# Espressif register map
File version: 1.0
CPU: Xtensa LX6 1, little endian, no MPU, FPU, 3 interrupt priority bits
Registers are 32-bit, access not given, reset 0x0 unless marked. A register's access mark holds for its fields unless they carry their own. Offsets are from the block's base; [hi:lo] are bit positions; {n}, {i} and the like mark numbered series.

## RTCCNTL
Base 0x3FF48000
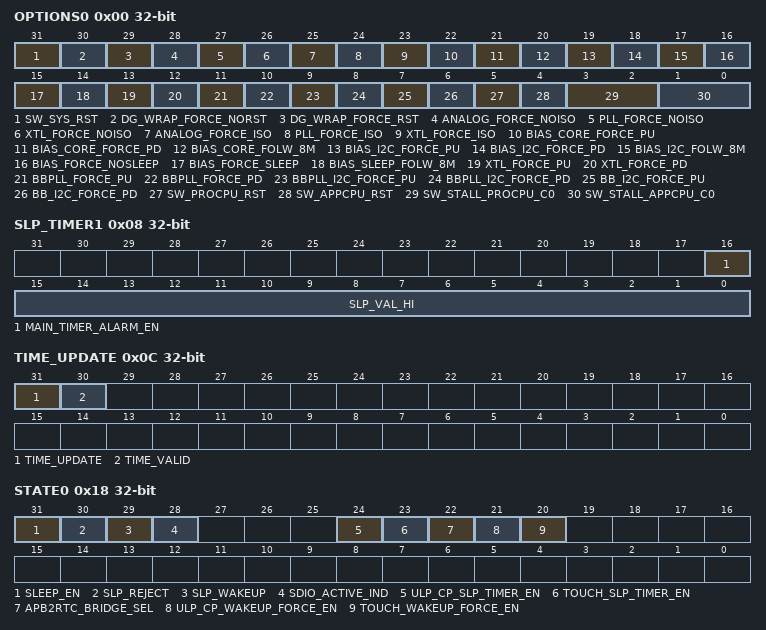
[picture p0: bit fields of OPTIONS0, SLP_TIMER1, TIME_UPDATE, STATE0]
0x00 OPTIONS0 — RTC_CNTL_OPTIONS0
  [31] SW_SYS_RST, [30] DG_WRAP_FORCE_NORST, [29] DG_WRAP_FORCE_RST, [28] ANALOG_FORCE_NOISO, [27] PLL_FORCE_NOISO, [26] XTL_FORCE_NOISO, [25] ANALOG_FORCE_ISO, [24] PLL_FORCE_ISO, [23] XTL_FORCE_ISO, [22] BIAS_CORE_FORCE_PU, [21] BIAS_CORE_FORCE_PD, [20] BIAS_CORE_FOLW_8M, [19] BIAS_I2C_FORCE_PU, [18] BIAS_I2C_FORCE_PD, [17] BIAS_I2C_FOLW_8M, [16] BIAS_FORCE_NOSLEEP, [15] BIAS_FORCE_SLEEP, [14] BIAS_SLEEP_FOLW_8M, [13] XTL_FORCE_PU, [12] XTL_FORCE_PD, [11] BBPLL_FORCE_PU, [10] BBPLL_FORCE_PD, [9] BBPLL_I2C_FORCE_PU, [8] BBPLL_I2C_FORCE_PD, [7] BB_I2C_FORCE_PU, [6] BB_I2C_FORCE_PD, [5] SW_PROCPU_RST, [4] SW_APPCPU_RST, [3:2] SW_STALL_PROCPU_C0, [1:0] SW_STALL_APPCPU_C0
0x04 SLP_TIMER0 — RTC_CNTL_SLP_TIMER0
  [31:0] SLP_VAL_LO
0x08 SLP_TIMER1 — RTC_CNTL_SLP_TIMER1
  [16] MAIN_TIMER_ALARM_EN, [15:0] SLP_VAL_HI
0x0C TIME_UPDATE — RTC_CNTL_TIME_UPDATE
  [31] TIME_UPDATE, [30] TIME_VALID
0x10 TIME0 — RTC_CNTL_TIME0
  [31:0] TIME_LO
0x14 TIME1 — RTC_CNTL_TIME1
  [15:0] TIME_HI
0x18 STATE0 — RTC_CNTL_STATE0
  [31] SLEEP_EN, [30] SLP_REJECT, [29] SLP_WAKEUP, [28] SDIO_ACTIVE_IND, [24] ULP_CP_SLP_TIMER_EN, [23] TOUCH_SLP_TIMER_EN, [22] APB2RTC_BRIDGE_SEL, [21] ULP_CP_WAKEUP_FORCE_EN, [20] TOUCH_WAKEUP_FORCE_EN
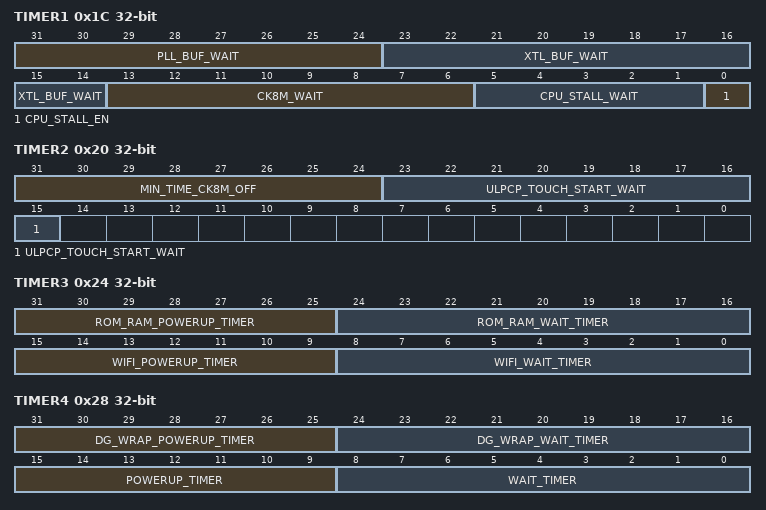
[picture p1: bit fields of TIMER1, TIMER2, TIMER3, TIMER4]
0x1C TIMER1 — RTC_CNTL_TIMER1
  [31:24] PLL_BUF_WAIT, [23:14] XTL_BUF_WAIT, [13:6] CK8M_WAIT, [5:1] CPU_STALL_WAIT, [0] CPU_STALL_EN
0x20 TIMER2 — RTC_CNTL_TIMER2
  [31:24] MIN_TIME_CK8M_OFF, [23:15] ULPCP_TOUCH_START_WAIT
0x24 TIMER3 — RTC_CNTL_TIMER3
  [31:25] ROM_RAM_POWERUP_TIMER, [24:16] ROM_RAM_WAIT_TIMER, [15:9] WIFI_POWERUP_TIMER, [8:0] WIFI_WAIT_TIMER
0x28 TIMER4 — RTC_CNTL_TIMER4
  [31:25] DG_WRAP_POWERUP_TIMER, [24:16] DG_WRAP_WAIT_TIMER, [15:9] POWERUP_TIMER, [8:0] WAIT_TIMER
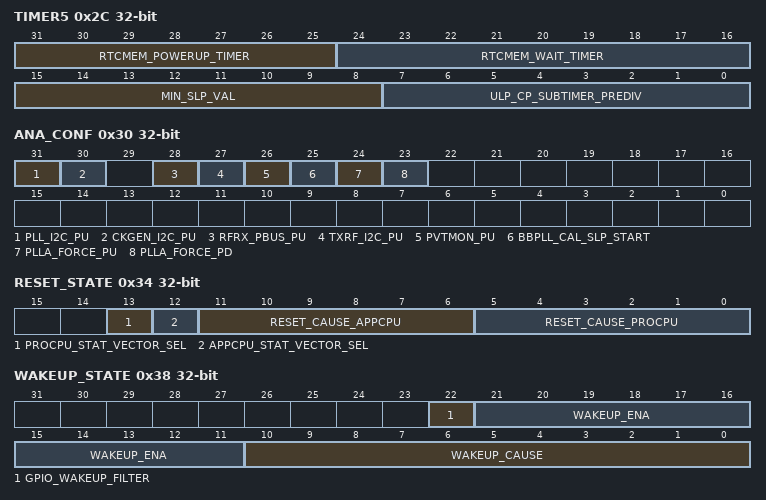
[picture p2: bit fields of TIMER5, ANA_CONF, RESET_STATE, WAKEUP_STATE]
0x2C TIMER5 — RTC_CNTL_TIMER5
  [31:25] RTCMEM_POWERUP_TIMER, [24:16] RTCMEM_WAIT_TIMER, [15:8] MIN_SLP_VAL, [7:0] ULP_CP_SUBTIMER_PREDIV
0x30 ANA_CONF — RTC_CNTL_ANA_CONF
  [31] PLL_I2C_PU, [30] CKGEN_I2C_PU, [28] RFRX_PBUS_PU, [27] TXRF_I2C_PU, [26] PVTMON_PU, [25] BBPLL_CAL_SLP_START, [24] PLLA_FORCE_PU, [23] PLLA_FORCE_PD
0x34 RESET_STATE — RTC_CNTL_RESET_STATE
  [13] PROCPU_STAT_VECTOR_SEL, [12] APPCPU_STAT_VECTOR_SEL, [11:6] RESET_CAUSE_APPCPU, [5:0] RESET_CAUSE_PROCPU
0x38 WAKEUP_STATE — RTC_CNTL_WAKEUP_STATE
  [22] GPIO_WAKEUP_FILTER, [21:11] WAKEUP_ENA, [10:0] WAKEUP_CAUSE
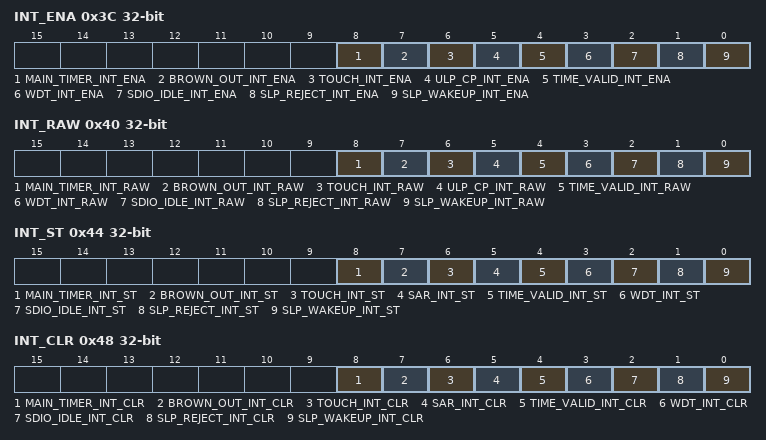
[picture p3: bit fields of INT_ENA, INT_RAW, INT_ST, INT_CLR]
0x3C INT_ENA — RTC_CNTL_INT_ENA
  [8] MAIN_TIMER_INT_ENA, [7] BROWN_OUT_INT_ENA, [6] TOUCH_INT_ENA, [5] ULP_CP_INT_ENA, [4] TIME_VALID_INT_ENA, [3] WDT_INT_ENA, [2] SDIO_IDLE_INT_ENA, [1] SLP_REJECT_INT_ENA, [0] SLP_WAKEUP_INT_ENA
0x40 INT_RAW — RTC_CNTL_INT_RAW
  [8] MAIN_TIMER_INT_RAW, [7] BROWN_OUT_INT_RAW, [6] TOUCH_INT_RAW, [5] ULP_CP_INT_RAW, [4] TIME_VALID_INT_RAW, [3] WDT_INT_RAW, [2] SDIO_IDLE_INT_RAW, [1] SLP_REJECT_INT_RAW, [0] SLP_WAKEUP_INT_RAW
0x44 INT_ST — RTC_CNTL_INT_ST
  [8] MAIN_TIMER_INT_ST, [7] BROWN_OUT_INT_ST, [6] TOUCH_INT_ST, [5] SAR_INT_ST, [4] TIME_VALID_INT_ST, [3] WDT_INT_ST, [2] SDIO_IDLE_INT_ST, [1] SLP_REJECT_INT_ST, [0] SLP_WAKEUP_INT_ST
0x48 INT_CLR — RTC_CNTL_INT_CLR
  [8] MAIN_TIMER_INT_CLR, [7] BROWN_OUT_INT_CLR, [6] TOUCH_INT_CLR, [5] SAR_INT_CLR, [4] TIME_VALID_INT_CLR, [3] WDT_INT_CLR, [2] SDIO_IDLE_INT_CLR, [1] SLP_REJECT_INT_CLR, [0] SLP_WAKEUP_INT_CLR
{0x4C+4i} STORE{i} (i=0..3) — RTC_CNTL_STORE{i}
  [31:0] SCRATCH{i}
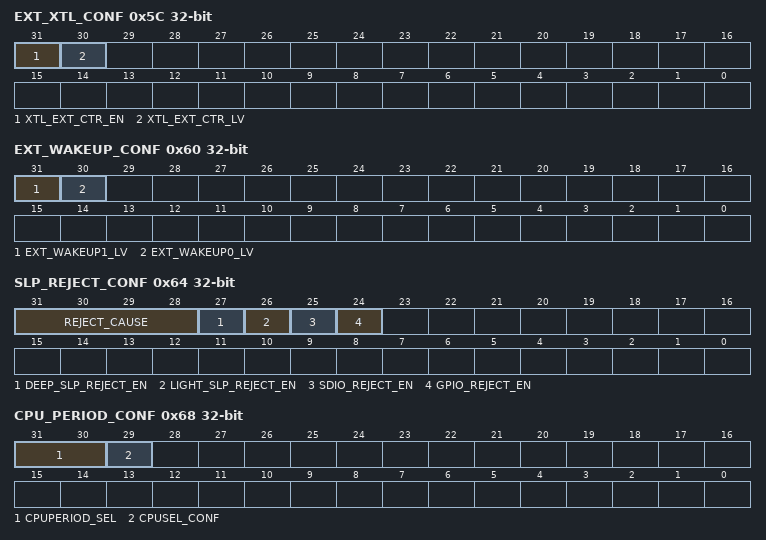
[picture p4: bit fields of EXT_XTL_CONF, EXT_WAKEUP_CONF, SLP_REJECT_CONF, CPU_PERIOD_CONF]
0x5C EXT_XTL_CONF — RTC_CNTL_EXT_XTL_CONF
  [31] XTL_EXT_CTR_EN, [30] XTL_EXT_CTR_LV
0x60 EXT_WAKEUP_CONF — RTC_CNTL_EXT_WAKEUP_CONF
  [31] EXT_WAKEUP1_LV, [30] EXT_WAKEUP0_LV
0x64 SLP_REJECT_CONF — RTC_CNTL_SLP_REJECT_CONF
  [31:28] REJECT_CAUSE, [27] DEEP_SLP_REJECT_EN, [26] LIGHT_SLP_REJECT_EN, [25] SDIO_REJECT_EN, [24] GPIO_REJECT_EN
0x68 CPU_PERIOD_CONF — RTC_CNTL_CPU_PERIOD_CONF
  [31:30] CPUPERIOD_SEL, [29] CPUSEL_CONF
0x6C SDIO_ACT_CONF — RTC_CNTL_SDIO_ACT_CONF
  [31:22] SDIO_ACT_DNUM
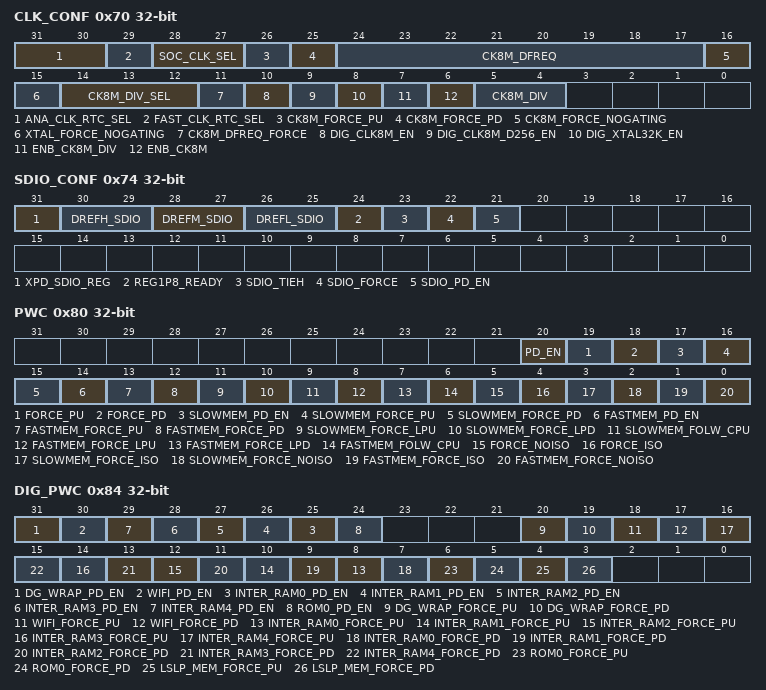
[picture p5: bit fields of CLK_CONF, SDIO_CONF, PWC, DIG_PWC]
0x70 CLK_CONF — RTC_CNTL_CLK_CONF
  [31:30] ANA_CLK_RTC_SEL, [29] FAST_CLK_RTC_SEL, [28:27] SOC_CLK_SEL, [26] CK8M_FORCE_PU, [25] CK8M_FORCE_PD, [24:17] CK8M_DFREQ, [16] CK8M_FORCE_NOGATING, [15] XTAL_FORCE_NOGATING, [14:12] CK8M_DIV_SEL, [11] CK8M_DFREQ_FORCE, [10] DIG_CLK8M_EN, [9] DIG_CLK8M_D256_EN, [8] DIG_XTAL32K_EN, [7] ENB_CK8M_DIV, [6] ENB_CK8M, [5:4] CK8M_DIV
0x74 SDIO_CONF — RTC_CNTL_SDIO_CONF
  [31] XPD_SDIO_REG, [30:29] DREFH_SDIO, [28:27] DREFM_SDIO, [26:25] DREFL_SDIO, [24] REG1P8_READY, [23] SDIO_TIEH, [22] SDIO_FORCE, [21] SDIO_PD_EN
0x78 BIAS_CONF — RTC_CNTL_BIAS_CONF
  [31] RST_BIAS_I2C, [31] FORCE_PU, [30] DEC_HEARTBEAT_WIDTH, [30] FORCE_PD, [29] INC_HEARTBEAT_PERIOD, [29] DBOOST_FORCE_PU, [28] DEC_HEARTBEAT_PERIOD, [28] DBOOST_FORCE_PD, [27] INC_HEARTBEAT_REFRESH, [26] ENB_SCK_XTAL, [27:25] DBIAS_WAK, [25:24] DBG_ATTEN, [24:22] DBIAS_SLP, [21:14] SCK_DCAP, [13:11] DIG_DBIAS_WAK, [10:8] DIG_DBIAS_SLP, [7] SCK_DCAP_FORCE
0x80 PWC — RTC_CNTL_PWC
  [20] PD_EN, [19] FORCE_PU, [18] FORCE_PD, [17] SLOWMEM_PD_EN, [16] SLOWMEM_FORCE_PU, [15] SLOWMEM_FORCE_PD, [14] FASTMEM_PD_EN, [13] FASTMEM_FORCE_PU, [12] FASTMEM_FORCE_PD, [11] SLOWMEM_FORCE_LPU, [10] SLOWMEM_FORCE_LPD, [9] SLOWMEM_FOLW_CPU, [8] FASTMEM_FORCE_LPU, [7] FASTMEM_FORCE_LPD, [6] FASTMEM_FOLW_CPU, [5] FORCE_NOISO, [4] FORCE_ISO, [3] SLOWMEM_FORCE_ISO, [2] SLOWMEM_FORCE_NOISO, [1] FASTMEM_FORCE_ISO, [0] FASTMEM_FORCE_NOISO
0x84 DIG_PWC — RTC_CNTL_DIG_PWC
  [31] DG_WRAP_PD_EN, [30] WIFI_PD_EN, [n+25] INTER_RAM{n}_PD_EN (n=0..4), [24] ROM0_PD_EN, [20] DG_WRAP_FORCE_PU, [19] DG_WRAP_FORCE_PD, [18] WIFI_FORCE_PU, [17] WIFI_FORCE_PD, [2n+8] INTER_RAM{n}_FORCE_PU (n=0..4), [2n+7] INTER_RAM{n}_FORCE_PD (n=0..4), [6] ROM0_FORCE_PU, [5] ROM0_FORCE_PD, [4] LSLP_MEM_FORCE_PU, [3] LSLP_MEM_FORCE_PD
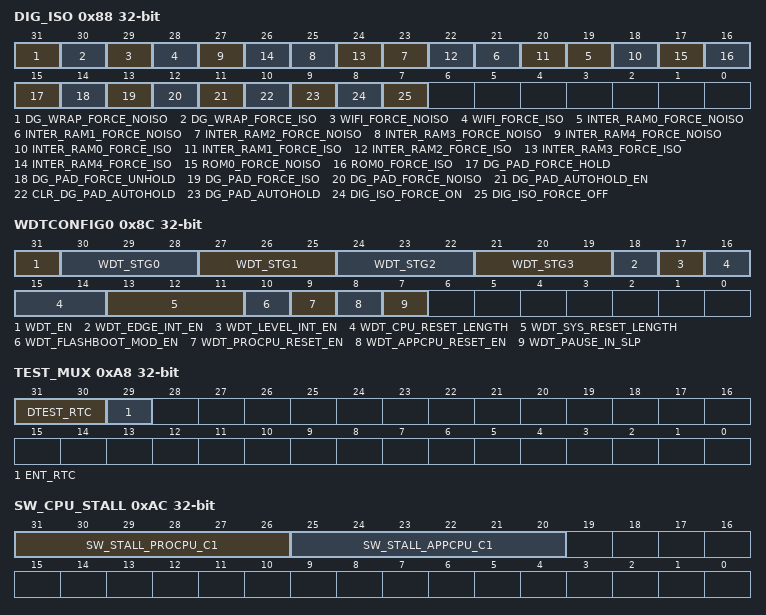
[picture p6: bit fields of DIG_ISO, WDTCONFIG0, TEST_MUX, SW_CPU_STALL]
0x88 DIG_ISO — RTC_CNTL_DIG_ISO
  [31] DG_WRAP_FORCE_NOISO, [30] DG_WRAP_FORCE_ISO, [29] WIFI_FORCE_NOISO, [28] WIFI_FORCE_ISO, [2n+19] INTER_RAM{n}_FORCE_NOISO (n=0..4), [2n+18] INTER_RAM{n}_FORCE_ISO (n=0..4), [17] ROM0_FORCE_NOISO, [16] ROM0_FORCE_ISO, [15] DG_PAD_FORCE_HOLD, [14] DG_PAD_FORCE_UNHOLD, [13] DG_PAD_FORCE_ISO, [12] DG_PAD_FORCE_NOISO, [11] DG_PAD_AUTOHOLD_EN, [10] CLR_DG_PAD_AUTOHOLD, [9] DG_PAD_AUTOHOLD, [8] DIG_ISO_FORCE_ON, [7] DIG_ISO_FORCE_OFF
0x8C WDTCONFIG0 — RTC_CNTL_WDTCONFIG0
  [31] WDT_EN, [30-3n:28-3n] WDT_STG{n} (n=0..3), [18] WDT_EDGE_INT_EN, [17] WDT_LEVEL_INT_EN, [16:14] WDT_CPU_RESET_LENGTH, [13:11] WDT_SYS_RESET_LENGTH, [10] WDT_FLASHBOOT_MOD_EN, [9] WDT_PROCPU_RESET_EN, [8] WDT_APPCPU_RESET_EN, [7] WDT_PAUSE_IN_SLP
{0x8C+4i} WDTCONFIG{i} (i=1..4) — RTC_CNTL_WDTCONFIG{i}
  [31:0] WDT_STG{i-1}_HOLD
0xA0 WDTFEED — RTC_CNTL_WDTFEED
  [31] WDT_FEED
0xA4 WDTWPROTECT — RTC_CNTL_WDTWPROTECT
  [31:0] WDT_WKEY
0xA8 TEST_MUX — RTC_CNTL_TEST_MUX
  [31:30] DTEST_RTC, [29] ENT_RTC
0xAC SW_CPU_STALL — RTC_CNTL_SW_CPU_STALL
  [31:26] SW_STALL_PROCPU_C1, [25:20] SW_STALL_APPCPU_C1
{0xA0+4i} STORE{i} (i=4..7) — RTC_CNTL_STORE{i}
  [31:0] SCRATCH{i}
0xC4 DIAG1 — RTC_CNTL_DIAG1
  [31:0] LOW_POWER_DIAG1
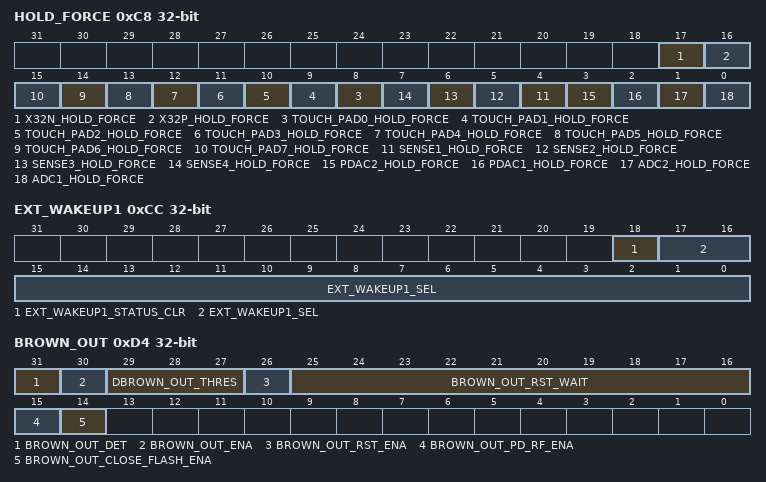
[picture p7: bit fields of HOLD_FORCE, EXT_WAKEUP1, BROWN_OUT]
0xC8 HOLD_FORCE — RTC_CNTL_HOLD_FORCE
  [17] X32N_HOLD_FORCE, [16] X32P_HOLD_FORCE, [n+8] TOUCH_PAD{n}_HOLD_FORCE (n=0..7), [n+3] SENSE{n}_HOLD_FORCE (n=1..4), [3] PDAC2_HOLD_FORCE, [2] PDAC1_HOLD_FORCE, [1] ADC2_HOLD_FORCE, [0] ADC1_HOLD_FORCE
0xCC EXT_WAKEUP1 — RTC_CNTL_EXT_WAKEUP1
  [18] EXT_WAKEUP1_STATUS_CLR, [17:0] EXT_WAKEUP1_SEL
0xD0 EXT_WAKEUP1_STATUS — RTC_CNTL_EXT_WAKEUP1_STATUS
  [17:0] EXT_WAKEUP1_STATUS
0xD4 BROWN_OUT — RTC_CNTL_BROWN_OUT
  [31] BROWN_OUT_DET, [30] BROWN_OUT_ENA, [29:27] DBROWN_OUT_THRES, [26] BROWN_OUT_RST_ENA, [25:16] BROWN_OUT_RST_WAIT, [15] BROWN_OUT_PD_RF_ENA, [14] BROWN_OUT_CLOSE_FLASH_ENA
0x13C DATE — RTC_CNTL_DATE
  [27:0] CNTL_DATE
